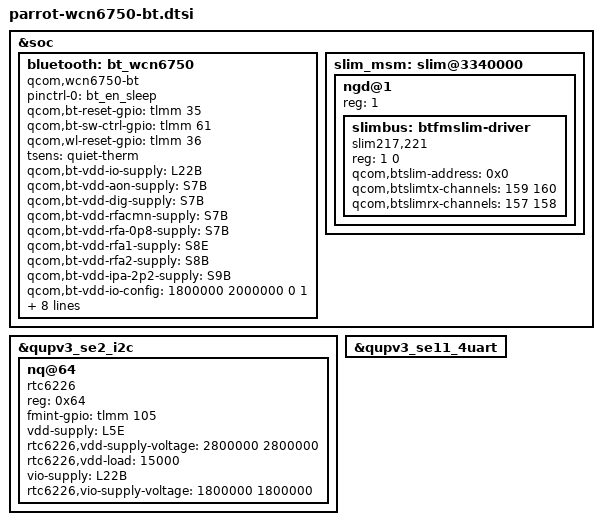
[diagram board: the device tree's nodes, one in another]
// SPDX-License-Identifier: BSD-3-Clause

/*
 * Copyright (c) 2024 Qualcomm Innovation Center, Inc. All rights reserved.
 */

#include <dt-bindings/interrupt-controller/arm-gic.h>

&soc {
	bluetooth: bt_wcn6750 {
		compatible = "qcom,wcn6750-bt";
		pinctrl-names = "default";
		pinctrl-0 = <&bt_en_sleep>;
		qcom,bt-reset-gpio = <&tlmm 35 0>; /* BT_EN */
		qcom,bt-sw-ctrl-gpio = <&tlmm 61 0>; /* SW_CTRL */
		qcom,wl-reset-gpio = <&tlmm 36 0>; /* WL_EN */
		tsens = "quiet-therm";

		qcom,bt-vdd-io-supply = <&L22B>;  /* IO */
		qcom,bt-vdd-aon-supply = <&S7B>;
		qcom,bt-vdd-dig-supply = <&S7B>; /* BT_CX_MX */
		qcom,bt-vdd-rfacmn-supply = <&S7B>;
		qcom,bt-vdd-rfa-0p8-supply = <&S7B>;
		qcom,bt-vdd-rfa1-supply = <&S8E>; /*RFA 1p7*/
		qcom,bt-vdd-rfa2-supply = <&S8B>; /*RFA 1p2*/
		qcom,bt-vdd-ipa-2p2-supply = <&S9B>; /*IPA 2p2*/
		//qcom,bt-vdd-asd-supply = <&L11C>;

		/* max voltage are set to regulator max voltage supported */
		qcom,bt-vdd-io-config = <1800000 2000000 0 1>;
		qcom,bt-vdd-aon-config = <824000 1174000 0 1>;
		qcom,bt-vdd-dig-config = <824000 1174000 0 1>;
		qcom,bt-vdd-rfacmn-config  = <824000 1174000 0 1>;
		qcom,bt-vdd-rfa-0p8-config  = <824000 1174000 0 1>;
		qcom,bt-vdd-rfa1-config = <1872000 2040000 0 1>;
		qcom,bt-vdd-rfa2-config = <1256000 1654000 0 1>;
		qcom,bt-vdd-ipa-2p2-config = <2200000 2208000 0 1>;
		//qcom,bt-vdd-asd-config = <2800000 3544000 0 1>;
	};

	slim_msm: slim@3340000 {
		status =  "ok";
		ngd@1 {
			reg = <1>;
			#address-cells = <1>;
			#size-cells = <1>;
			//slimbus child nodes
			slimbus: btfmslim-driver {
				compatible = "slim217,221";
				reg = <1 0>;
				qcom,btslim-address  = <0x0>; /* BT SLIM EP address*/
				qcom,btslimtx-channels = <159 160>;
				qcom,btslimrx-channels = <157 158>;
			};
		};
	};
};

//FM changes
&qupv3_se2_i2c {
	status = "ok";
	nq@64 {
		compatible = "rtc6226";
		reg = <0x64>;
		fmint-gpio = <&tlmm 105 0>;
		vdd-supply = <&L5E>;
		rtc6226,vdd-supply-voltage = <2800000 2800000>;
		rtc6226,vdd-load = <15000>;
		vio-supply = <&L22B>;
		rtc6226,vio-supply-voltage = <1800000 1800000>;
	};
};

//uart instance
&qupv3_se11_4uart {
	status = "ok";
};

